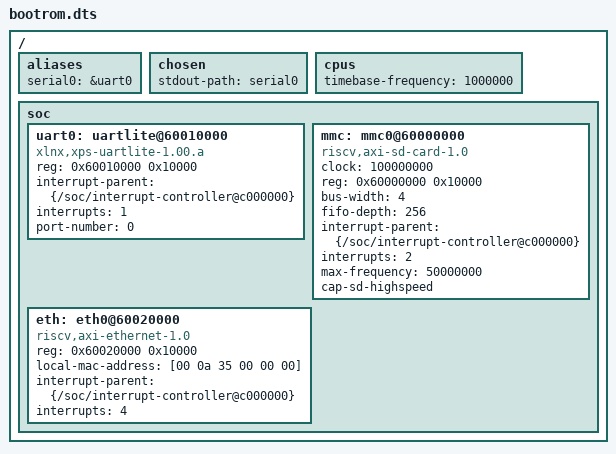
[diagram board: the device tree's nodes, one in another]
/ {

    aliases {
        serial0 = &uart0;
    };

    chosen {
        stdout-path = "serial0";
    };

    cpus {
        timebase-frequency = <1000000>;
    };

    soc {
        #address-cells = <1>;
        #size-cells = <1>;

        uart0: uartlite@60010000 {
            compatible = "xlnx,xps-uartlite-1.00.a";
            reg = <0x60010000 0x10000>;
            interrupt-parent = <&{/soc/interrupt-controller@c000000}>;
            interrupts = <1>;
            port-number = <0>;
        };

        mmc: mmc0@60000000 {
            compatible = "riscv,axi-sd-card-1.0";
            clock = <100000000>;
            reg = <0x60000000 0x10000>;
            bus-width = <4>;
            fifo-depth = <256>;
            interrupt-parent = <&{/soc/interrupt-controller@c000000}>;
            interrupts = <2>;
            max-frequency = <50000000>;
            cap-sd-highspeed;
        };

        eth: eth0@60020000 {
            compatible = "riscv,axi-ethernet-1.0";
            reg = <0x60020000 0x10000>;
            local-mac-address = [00 0a 35 00 00 00];
            interrupt-parent = <&{/soc/interrupt-controller@c000000}>;
            interrupts = <4>;
        };
    };
};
